# RZT2H register map
Vendor: Renesas Electronics Corporation; Series: RZT; File version: 1.00.00
CPU: other r0p0, little endian, MPU, no FPU, VTOR, 4 interrupt priority bits, 624 interrupts
Registers are 32-bit, read-write, reset 0x0 unless marked. A register's access mark holds for its fields unless they carry their own. Offsets are from the block's base; [hi:lo] are bit positions; {n}, {i} and the like mark numbered series; 'fields as' and 'values as' point back to an identical list.

## SYSC_NS — System Control for Non-safety region
Base 0x80280000
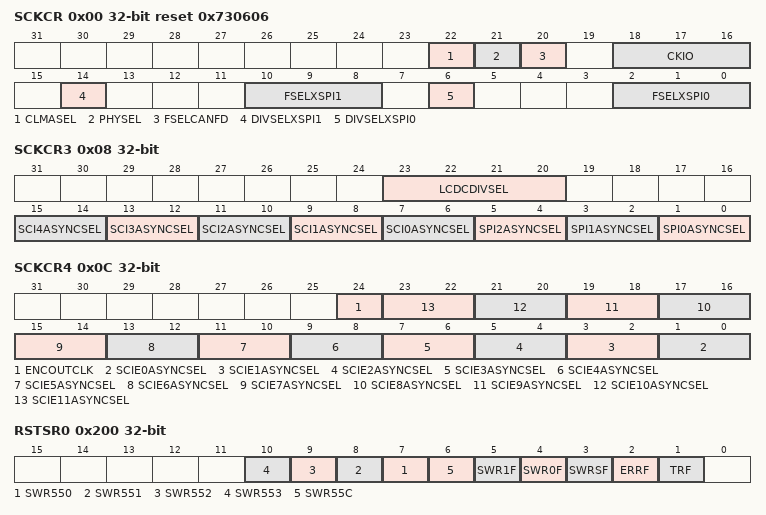
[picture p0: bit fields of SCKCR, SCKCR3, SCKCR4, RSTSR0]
0x00 SCKCR reset 0x730606 — System Clock Control Register
  [22] CLMASEL — Select alternative clock when main clock abnormal oscillation is detected in CLMA6
    0=LOCO; 1=PLL
  [21] PHYSEL — Select the Ethernet PHY reference clock output (ETHn_REFCLK, n = 0 to 3)
    0=PLL1 divider clock; 1=Main clock oscillator
  [20] FSELCANFD — Select the frequency of the clock supplied to CANFD
    0=80.0 MHz; 1=40.0 MHz
  [18:16] CKIO — Set the frequency of the external bus clock (CKIO) and the clock supplied to BSC.
  [14] DIVSELXSPI1 — Select the base clock to generate serial clock for xSPI Unit 1
    0=800 MHz; 1=600 MHz
  [10:8] FSELXSPI1 — Set the frequency of the clock provided to xSPI Unit 1 in combination with bit 14 (DIVSELXSPI1).
  [6] DIVSELXSPI0 — Select the base clock to generate serial clock for xSPI Unit 0
    0=800 MHz; 1=600 MHz
  [2:0] FSELXSPI0 — Set the frequency of the clock provided to xSPI Unit 0 in combination with bit 6 (DIVSELXSPI0). The combination is shown below.
0x08 SCKCR3 — System Clock Control Register 3
  [23:20] LCDCDIVSEL
    0=1/2; 1=1/4; 2=1/6; 3=1/8; 4=1/10; 5=1/12; 6=1/14; 7=1/16; 8=1/18; 9=1/20; 10=1/22; 11=1/24; 12=1/26; 13=1/28; 14=1/30; 15=1/32
  [2n+7:2n+6] SCI{n}ASYNCSEL (n=0..4)
    0=75.0 MHz; 1=80.0 MHz; 2=96.0 MHz; 3=100.0 MHz
  [5:4] SPI2ASYNCSEL
    0=75.0 MHz; 1=80.0 MHz; 2=96.0 MHz; 3=100.0 MHz
  [3:2] SPI1ASYNCSEL
    0=75.0 MHz; 1=80.0 MHz; 2=96.0 MHz; 3=100.0 MHz
  [1:0] SPI0ASYNCSEL
    0=75.0 MHz; 1=80.0 MHz; 2=96.0 MHz; 3=100.0 MHz
0x0C SCKCR4 — System Clock Control Register 4
  [24] ENCOUTCLK
    0=20.0 MHz; 1=80.0 MHz
  [2n+1:2n] SCIE{n}ASYNCSEL (n=0..11)
    0=75.0 MHz; 1=80.0 MHz; 2=96.0 MHz; 3=100.0 MHz
0x200 RSTSR0 (reset mask 0xFFFFF801) — Reset Status Register 0
  [n-543] SWR{n} (n=550..553) — Cortex-A55 Core{n-550} Software Reset Detect Flag
    0=Cortex-A55 Core{n-550} software reset no detected; 1=Cortex-A55 Core{n-550} software reset detected
  [6] SWR55C — Cortex-A55 Cluster Software Reset Detect Flag
    0=Cortex-A55 Cluster software reset no detected; 1=Cortex-A55 Cluster software reset detected
  [5] SWR1F — Cortex-R52 CPU1 Software Reset Detect Flag
    0=Cortex-R52 CPU1 software reset not detected; 1=Cortex-R52 CPU1 software reset detected
  [4] SWR0F — Cortex-R52 CPU0 Software Reset Detect Flag
    0=Cortex-R52 CPU0 software reset not detected; 1=Cortex-R52 CPU0 software reset detected
  [3] SWRSF — System Software Reset Detect Flag
    0=System software reset not detected; 1=System software reset detected
  [2] ERRF — Error Reset Detect Flag
    0=Error reset not detected; 1=Error reset detected
  [1] TRF — RES# Pin Reset Detect Flag
    0=RES# pin reset not detected; 1=RES# pin reset detected
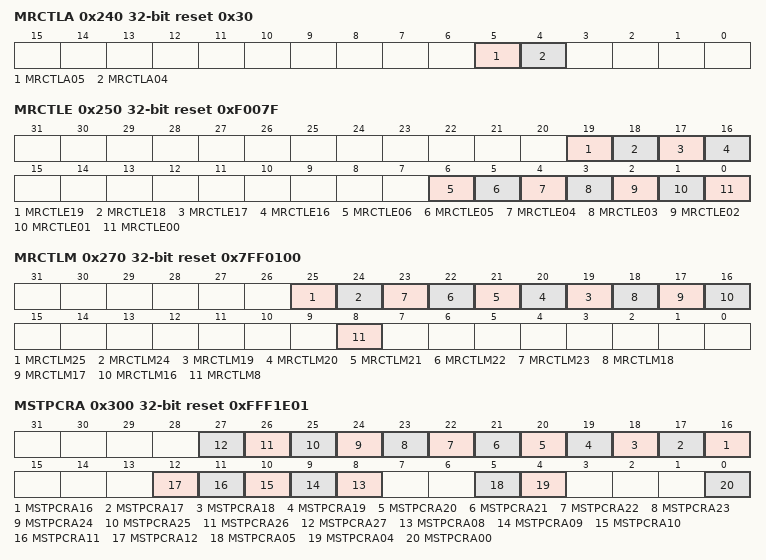
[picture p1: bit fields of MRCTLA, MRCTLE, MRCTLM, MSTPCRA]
0x240 MRCTLA reset 0x30 — Module Reset Control Register A
  [5] MRCTLA05 — xSPI Unit 1 Reset Control
    0=xSPI Unit 1 is released from reset; 1=xSPI Unit 1 is in the reset state
  [4] MRCTLA04 — xSPI Unit 0 Reset Control
    0=xSPI Unit 0 is released from reset; 1=xSPI Unit 0 is in the reset state
0x250 MRCTLE reset 0xF007F — Module Reset Control Register E
  [19] MRCTLE19 — GMAC Unit 2 (PCLKAM clock domain) Reset Control
    0=GMAC Unit 2 (PCLKAM clock domain) is released from reset; 1=GMAC Unit 2 (PCLKAM clock domain) is in the reset state
  [18] MRCTLE18 — GMAC Unit 2 (PCLKAH clock domain) Reset Control
    0=GMAC Unit 1 (PCLKAH clock domain) is released from reset; 1=GMAC Unit 1 (PCLKAH clock domain) is in the reset state
  [17] MRCTLE17 — GMAC Unit 1 (PCLKAM clock domain) Reset Control
    0=GMAC Unit 1 (PCLKAM clock domain) is released from reset; 1=GMAC Unit 1 (PCLKAM clock domain) is in the reset state
  [16] MRCTLE16 — GMAC Unit 1 (PCLKAH clock domain) Reset Control
    values as MRCTLE18
  [6] MRCTLE06 — MII Converter Reset Control
    0=MII converter is released from reset; 1=MII converter is in the reset state
  [5] MRCTLE05 — Ethernet Subsystem Register Reset Control
    0=Ethernet Subsystem register is released from reset; 1=Ethernet Subsystem register is in the reset state
  [4] MRCTLE04 — ESC (IP clock domain) Reset Control
    0=ESC (IP clock domain) is released from reset; 1=ESC (IP clock domain) is in the reset state
  [3] MRCTLE03 — ESC (Bus clock domain) Reset Control
    0=ESC (Bus clock domain) is released from reset; 1=ESC (Bus clock domain) is in the reset state
  [2] MRCTLE02 — ETHSW Reset Control
    0=ETHSW is released from reset; 1=ETHSW is in the reset state
  [1] MRCTLE01 — GMAC Unit 0 (PCLKM clock domain) Reset Control
    0=GMAC Unit 0 (PCLKM clock domain) is released from reset; 1=GMAC Unit 0 (PCLKM clock domain) is in the reset state
  [0] MRCTLE00 — GMAC Unit 0 (PCLKH clock domain) Reset Control
    0=GMAC Unit 0 (PCLKH clock domain) is released from reset; 1=GMAC Unit 0 (PCLKH clock domain) is in the reset state
0x270 MRCTLM reset 0x7FF0100 — Module Reset Control Register M
  [25] MRCTLM25 — DDRSS (PHY_PRESETn) Reset Control
    0=DDRSS (PHY_PRESETn) is released from reset; 1=DDRSS (PHY_PRESETn) is in the reset state
  [24] MRCTLM24 — DDRSS (MC_PRESETn) Reset Control
    0=DDRSS (MC_PRESETn) is released from reset; 1=DDRSS (MC_PRESETn) is in the reset state
  [n] MRCTLM{n} (n=19..23) — DDRSS (axi{n-19}_ARESETn) Reset Control
    0=DDRSS (axi{n-19}_ARESETn) is released from reset; 1=DDRSS (axi{n-19}_ARESETn) is in the reset state
  [18] MRCTLM18 — DDRSS (Reset) Reset Control
    0=DDRSS (Reset) is released from reset; 1=DDRSS (Reset) is in the reset state
  [17] MRCTLM17 — DDRSS (PwrOkIn) Reset Control
    0=DDRSS (PwrOkIn) is released from reset; 1=DDRSS (PwrOkIn) is in the reset state
  [16] MRCTLM16 — DDRSS (rst_n) Reset Control
    0=DDRSS (rst_n) is released from reset; 1=DDRSS (rst_n) is in the reset state
  [8] MRCTLM8 — PCIE Reset Control
    0=PCIE is released from reset; 1=PCIE is in the reset state
0x300 MSTPCRA reset 0xFFF1E01 (reset mask 0xFFFFFECF) — Module Stop Control Register A
  [all] fields
    0=Release from the module-stop state; 1=Transition to the module-stop state is made
  [n] MSTPCRA{n} (n=16..27) — SCIE Unit {n-16} Module Stop
  [n] MSTPCRA{n:02} (n=8..12) — SCI Unit {n-8} Module Stop
  [5] MSTPCRA05 — xSPI Unit 1 Module Stop
  [4] MSTPCRA04 — xSPI Unit 0 Module Stop
  [0] MSTPCRA00 — BSC Module Stop
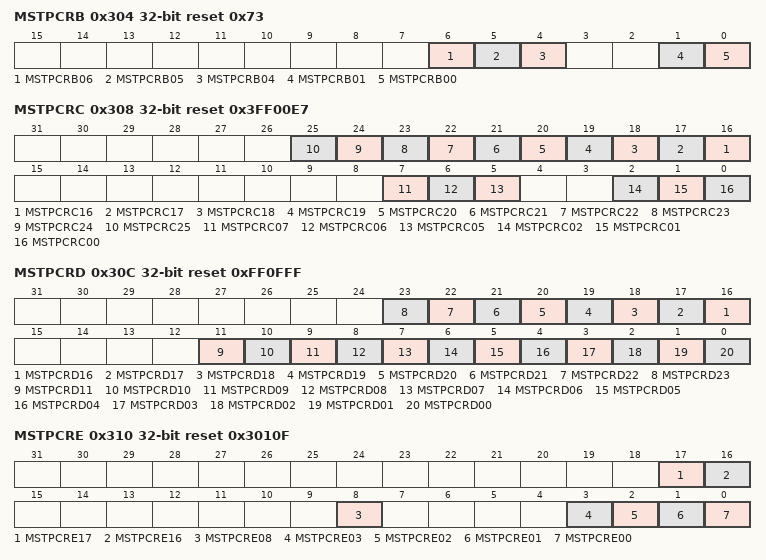
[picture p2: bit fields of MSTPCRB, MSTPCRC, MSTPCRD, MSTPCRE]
0x304 MSTPCRB reset 0x73 — Module Stop Control Register B
  [all] fields
    values as the fields of MSTPCRA
  [6] MSTPCRB06 — SPI Unit 2 Module Stop
  [5] MSTPCRB05 — SPI Unit 1 Module Stop
  [4] MSTPCRB04 — SPI Unit 0 Module Stop
  [1] MSTPCRB01 — IIC Unit 1 Module Stop
  [0] MSTPCRB00 — IIC Unit 0 Module Stop
0x308 MSTPCRC reset 0x3FF00E7 — Module Stop Control Register C
  [all] fields
    values as the fields of MSTPCRA
  [n] MSTPCRC{n} (n=16..25)
  [7] MSTPCRC07 — ADC12 Unit 1 Module Stop
  [6] MSTPCRC06 — ADC12 Unit 0 Module Stop
  [5] MSTPCRC05 — TFU Unit 0 Module Stop
  [2] MSTPCRC02 — GPT Unit 1 Module Stop
  [1] MSTPCRC01 — GPT Unit 0 Module Stop
  [0] MSTPCRC00 — MTU3 Module Stop
0x30C MSTPCRD reset 0xFF0FFF — Module Stop Control Register D
  [n] MSTPCRD{n} (n=16..23) — DSMIF Unit {n-14} Module Stop
    values as the fields of MSTPCRA
  [11] MSTPCRD11 — CKIO Module Stop
    values as the fields of MSTPCRA
  [10] MSTPCRD10 — CANFD Module Stop
    0=Release from the module-stop state; 1=Transition to the module stop state is made
  [9] MSTPCRD09 — CRC Unit 0 Module Stop
    values as the fields of MSTPCRA
  [8] MSTPCRD08 — DOC Module Stop
    values as the fields of MSTPCRA
  [7] MSTPCRD07 — TSU Module Stop
    values as MSTPCRD10
  [6] MSTPCRD06 — CMTW Unit 1 Module Stop
    values as the fields of MSTPCRA
  [5] MSTPCRD05 — CMTW Unit 0 Module Stop
    values as the fields of MSTPCRA
  [4] MSTPCRD04 — CMT Unit 2 Module Stop
    values as the fields of MSTPCRA
  [3] MSTPCRD03 — CMT Unit 1 Module Stop
    values as the fields of MSTPCRA
  [2] MSTPCRD02 — CMT Unit 0 Module Stop
    values as the fields of MSTPCRA
  [1] MSTPCRD01 — DSMIF Unit 1 Module Stop
    values as the fields of MSTPCRA
  [0] MSTPCRD00 — DSMIF Unit 0 Module Stop
    values as the fields of MSTPCRA
0x310 MSTPCRE reset 0x3010F — Module Stop Control Register E
  [all] fields
    values as the fields of MSTPCRA
  [17] MSTPCRE17 — GMAC Unit 2 Module Stop
  [16] MSTPCRE16 — GMAC Unit 1 Module Stop
  [8] MSTPCRE08 — USB Module Stop
  [3] MSTPCRE03 — Ethernet Subsystem Register Module Stop
  [2] MSTPCRE02 — ESC Module Stop
  [1] MSTPCRE01 — ETHSW Module Stop
  [0] MSTPCRE00 — GMAC Unit 0 Module Stop
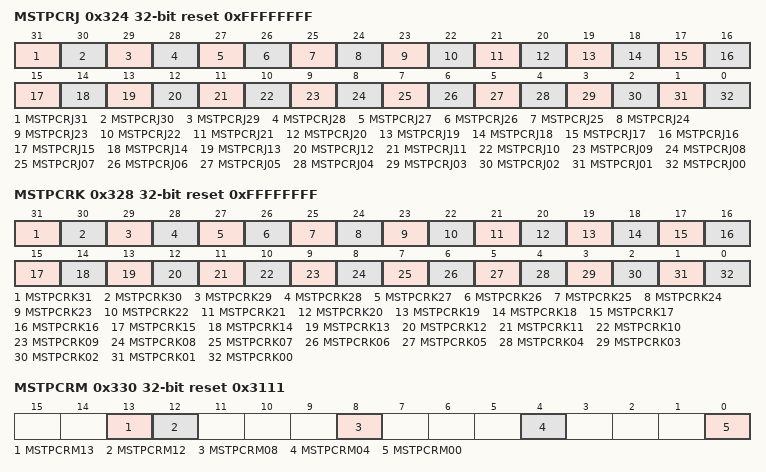
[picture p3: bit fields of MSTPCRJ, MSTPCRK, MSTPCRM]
0x324 MSTPCRJ reset 0xFFFFFFFF — Module Stop Control Register J
  [all] fields
    values as the fields of MSTPCRA
  [31] MSTPCRJ31 — ENDAT Unit 7 Module Stop
  [30] MSTPCRJ30 — BISS Unit 7 Module Stop
  [29] MSTPCRJ29 — HDSL Unit 7 Module Stop
  [28] MSTPCRJ28 — AFMT Unit 7 Module Stop
  [27] MSTPCRJ27 — ENDAT Unit 6 Module Stop
  [26] MSTPCRJ26 — BISS Unit 6 Module Stop
  [25] MSTPCRJ25 — HDSL Unit 6 Module Stop
  [24] MSTPCRJ24 — AFMT Unit 6 Module Stop
  [23] MSTPCRJ23 — ENDAT Unit 5 Module Stop
  [22] MSTPCRJ22 — BISS Unit 5 Module Stop
  [21] MSTPCRJ21 — HDSL Unit 5 Module Stop
  [20] MSTPCRJ20 — AFMT Unit 5 Module Stop
  [19] MSTPCRJ19 — ENDAT Unit 4 Module Stop
  [18] MSTPCRJ18 — BISS Unit 4 Module Stop
  [17] MSTPCRJ17 — HDSL Unit 4 Module Stop
  [16] MSTPCRJ16 — AFMT Unit 4 Module Stop
  [15] MSTPCRJ15 — ENDAT Unit 3 Module Stop
  [14] MSTPCRJ14 — BISS Unit 3 Module Stop
  [13] MSTPCRJ13 — HDSL Unit 3 Module Stop
  [12] MSTPCRJ12 — AFMT Unit 3 Module Stop
  [11] MSTPCRJ11 — ENDAT Unit 2 Module Stop
  [10] MSTPCRJ10 — BISS Unit 2 Module Stop
  [9] MSTPCRJ09 — HDSL Unit 2 Module Stop
  [8] MSTPCRJ08 — AFMT Unit 2 Module Stop
  [7] MSTPCRJ07 — ENDAT Unit 1 Module Stop
  [6] MSTPCRJ06 — BISS Unit 1 Module Stop
  [5] MSTPCRJ05 — HDSL Unit 1 Module Stop
  [4] MSTPCRJ04 — AFMT Unit 1 Module Stop
  [3] MSTPCRJ03 — ENDAT Unit 0 Module Stop
  [2] MSTPCRJ02 — BISS Unit 0 Module Stop
  [1] MSTPCRJ01 — HDSL Unit 0 Module Stop
  [0] MSTPCRJ00 — AFMT Unit 0 Module Stop
0x328 MSTPCRK reset 0xFFFFFFFF — Module Stop Control Register K
  [all] fields
    values as the fields of MSTPCRA
  [31] MSTPCRK31 — ENDAT Unit 15 Module Stop
  [30] MSTPCRK30 — BISS Unit 15 Module Stop
  [29] MSTPCRK29 — HDSL Unit 15 Module Stop
  [28] MSTPCRK28 — AFMT Unit 15 Module Stop
  [27] MSTPCRK27 — ENDAT Unit 14 Module Stop
  [26] MSTPCRK26 — BISS Unit 14 Module Stop
  [25] MSTPCRK25 — HDSL Unit 14 Module Stop
  [24] MSTPCRK24 — AFMT Unit 14 Module Stop
  [23] MSTPCRK23 — ENDAT Unit 13 Module Stop
  [22] MSTPCRK22 — BISS Unit 13 Module Stop
  [21] MSTPCRK21 — HDSL Unit 13 Module Stop
  [20] MSTPCRK20 — AFMT Unit 13 Module Stop
  [19] MSTPCRK19 — ENDAT Unit 12 Module Stop
  [18] MSTPCRK18 — BISS Unit 12 Module Stop
  [17] MSTPCRK17 — HDSL Unit 12 Module Stop
  [16] MSTPCRK16 — AFMT Unit 12 Module Stop
  [15] MSTPCRK15 — ENDAT Unit 11 Module Stop
  [14] MSTPCRK14 — BISS Unit 11 Module Stop
  [13] MSTPCRK13 — HDSL Unit 11 Module Stop
  [12] MSTPCRK12 — AFMT Unit 11 Module Stop
  [11] MSTPCRK11 — ENDAT Unit 10 Module Stop
  [10] MSTPCRK10 — BISS Unit 10 Module Stop
  [9] MSTPCRK09 — HDSL Unit 10 Module Stop
  [8] MSTPCRK08 — AFMT Unit 10 Module Stop
  [7] MSTPCRK07 — ENDAT Unit 9 Module Stop
  [6] MSTPCRK06 — BISS Unit 9 Module Stop
  [5] MSTPCRK05 — HDSL Unit 9 Module Stop
  [4] MSTPCRK04 — AFMT Unit 9 Module Stop
  [3] MSTPCRK03 — ENDAT Unit 8 Module Stop
  [2] MSTPCRK02 — BISS Unit 8 Module Stop
  [1] MSTPCRK01 — HDSL Unit 8 Module Stop
  [0] MSTPCRK00 — AFMT Unit 8 Module Stop
0x32C MSTPCRL reset 0x1 — Module Stop Control Register L
  [0] MSTPCRL00 — ENCOUT Module Stop
    values as the fields of MSTPCRA
0x330 MSTPCRM reset 0x3111 — Module Stop Control Register M
  [all] fields
    values as the fields of MSTPCRA
  [13] MSTPCRM13 — SDHI Unit 1 Module Stop
  [12] MSTPCRM12 — SDHI Unit 0 Module Stop
  [8] MSTPCRM08 — PCIE Module Stop
  [4] MSTPCRM04 — LCDC Module Stop
  [0] MSTPCRM00 — DDRSS Module Stop
